VERSION "1.0"

NS_ :

BS_:

BU_: GATEWAY SIM_PLANT

BO_ 1792 SIM_Inject: 8 GATEWAY
 SG_ FaultId : 0|8@1+ (1,0) [0|5] "" SIM_PLANT
 SG_ Value : 8|16@1- (1,0) [-32768|32767] "" SIM_PLANT

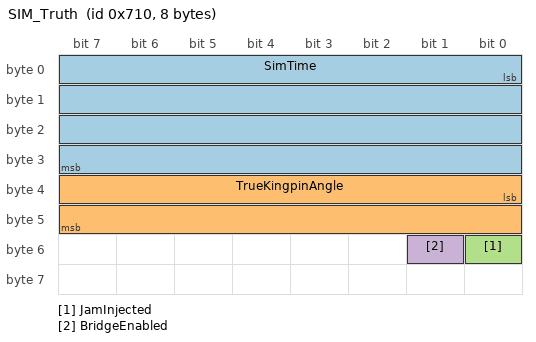
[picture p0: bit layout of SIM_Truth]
BO_ 1808 SIM_Truth: 8 SIM_PLANT
 SG_ SimTime : 0|32@1+ (1e-06,0) [0|4294.967295] "s" GATEWAY
 SG_ TrueKingpinAngle : 32|16@1- (0.001,0) [-32.768|32.767] "rad" GATEWAY
 SG_ JamInjected : 48|1@1+ (1,0) [0|1] "" GATEWAY
 SG_ BridgeEnabled : 49|1@1+ (1,0) [0|1] "" GATEWAY

BO_ 1824 SIM_Step: 8 GATEWAY
 SG_ TickCount : 0|16@1+ (1,0) [1|1000] "" SIM_PLANT

BO_ 1840 SIM_StepDone: 8 SIM_PLANT
 SG_ SimTime : 0|32@1+ (1e-06,0) [0|4294.967295] "s" GATEWAY

CM_ BO_ 1792 "SIL only: fault injection into the simulated plant, sensors and runtime.";
CM_ BO_ 1808 "SIL only: simulated time and ground truth, sent every 1 ms tick after that tick's ECU frames.";
CM_ BO_ 1824 "SIL only (lockstep mode): run TickCount control ticks, then answer with SIM_StepDone.";
CM_ BO_ 1840 "SIL only (lockstep mode): sent after the last tick of a SIM_Step; SimTime is the start of the next tick.";
VAL_ 1792 FaultId 0 "CLEAR" 1 "JAM" 2 "MOTOR_ENCODER_FREEZE" 3 "KINGPIN_ENCODER_OFFSET" 4 "KINGPIN_SENSOR_STALE" 5 "STEERING_OVERRUN" ;
